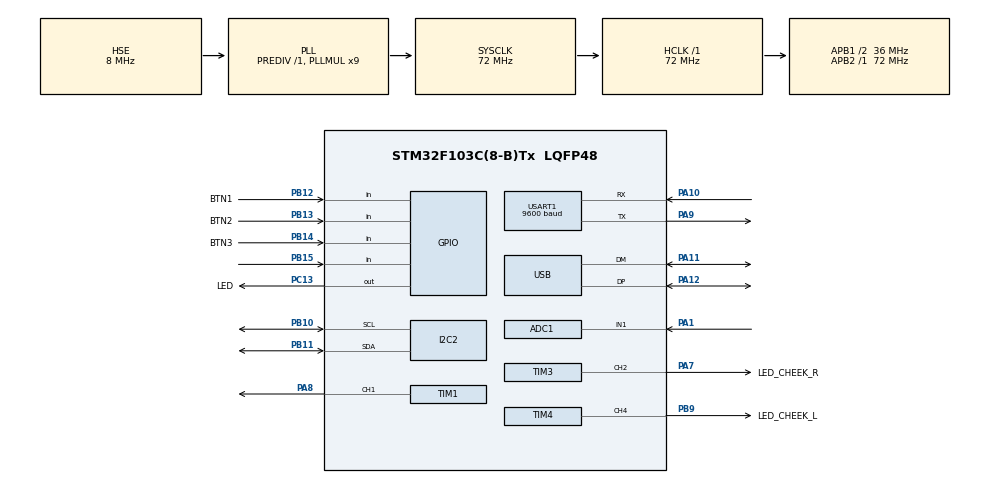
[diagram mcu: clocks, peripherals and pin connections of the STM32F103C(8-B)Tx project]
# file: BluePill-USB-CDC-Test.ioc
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ADC1.Channel-1\#ChannelRegularConversion=ADC_CHANNEL_1
ADC1.NbrOfConversionFlag=1
ADC1.Rank-1\#ChannelRegularConversion=1
ADC1.SamplingTime-1\#ChannelRegularConversion=ADC_SAMPLETIME_1CYCLE_5
ADC1.master=1
I2C2.I2C_Mode=I2C_Fast
Mcu.Family=STM32F1
Mcu.Name=STM32F103C(8-B)Tx
Mcu.Package=LQFP48
NVIC.PriorityGroup=NVIC_PRIORITYGROUP_4
NVIC.USB_LP_CAN1_RX0_IRQn=true\:0\:0\:false\:false\:true\:false\:true\:true
PA1.Signal=ADCx_IN1
PA10.Mode=Asynchronous
PA10.Signal=USART1_RX
PA11.Mode=Device
PA11.Signal=USB_DM
PA12.Mode=Device
PA12.Signal=USB_DP
PA13.Mode=Serial_Wire
PA13.Signal=SYS_JTMS-SWDIO
PA14.Mode=Serial_Wire
PA14.Signal=SYS_JTCK-SWCLK
PA7.GPIO_Label=LED_CHEEK_R
PA7.Signal=S_TIM3_CH2
PA8.Signal=S_TIM1_CH1
PA9.Mode=Asynchronous
PA9.Signal=USART1_TX
PB10.Mode=I2C
PB10.Signal=I2C2_SCL
PB11.Mode=I2C
PB11.Signal=I2C2_SDA
PB12.GPIO_Label=BTN1
PB12.Signal=GPIO_Input
PB13.GPIO_Label=BTN2
PB13.Signal=GPIO_Input
PB14.GPIO_Label=BTN3
PB14.Signal=GPIO_Input
PB15.Signal=GPIO_Input
PB9.GPIO_Label=LED_CHEEK_L
PB9.Signal=S_TIM4_CH4
PC13-TAMPER-RTC.GPIO_Label=LED
PC13-TAMPER-RTC.GPIO_PuPd=GPIO_PULLUP
PC13-TAMPER-RTC.PinState=GPIO_PIN_RESET
PC13-TAMPER-RTC.Signal=GPIO_Output
PD0-OSC_IN.Mode=HSE-External-Oscillator
PD0-OSC_IN.Signal=RCC_OSC_IN
PD1-OSC_OUT.Mode=HSE-External-Oscillator
PD1-OSC_OUT.Signal=RCC_OSC_OUT
ProjectManager.HeapSize=0x200
ProjectManager.StackSize=0x400
ProjectManager.TargetToolchain=STM32CubeIDE
RCC.AHBFreq_Value=72000000
RCC.APB1CLKDivider=RCC_HCLK_DIV2
RCC.APB1Freq_Value=36000000
RCC.APB1TimFreq_Value=72000000
RCC.APB2Freq_Value=72000000
RCC.APB2TimFreq_Value=72000000
RCC.HCLKFreq_Value=72000000
RCC.PLLMUL=RCC_PLL_MUL9
RCC.PLLSourceVirtual=RCC_PLLSOURCE_HSE
RCC.SYSCLKFreq_VALUE=72000000
RCC.SYSCLKSource=RCC_SYSCLKSOURCE_PLLCLK
RCC.USBFreq_Value=48000000
RCC.USBPrescaler=RCC_USBCLKSOURCE_PLL_DIV1_5
SH.ADCx_IN1.0=ADC1_IN1,IN1
SH.S_TIM1_CH1.0=TIM1_CH1,PWM Generation1 CH1
SH.S_TIM3_CH2.0=TIM3_CH2,PWM Generation2 CH2
SH.S_TIM4_CH4.0=TIM4_CH4,PWM Generation4 CH4
TIM1.Channel-PWM\ Generation1\ CH1=TIM_CHANNEL_1
TIM3.Channel-PWM\ Generation2\ CH2=TIM_CHANNEL_2
TIM4.Channel-PWM\ Generation4\ CH4=TIM_CHANNEL_4
USART1.BaudRate=9600
USART1.VirtualMode=VM_ASYNC
USB_DEVICE.CLASS_NAME_FS=CDC
USB_DEVICE.PRODUCT_STRING_CDC_FS=Test Product
USB_DEVICE.VirtualMode=Cdc
USB_DEVICE.VirtualModeFS=Cdc_FS
VP_RTC_VS_RTC_Activate.Mode=RTC_Enabled
VP_USB_DEVICE_VS_USB_DEVICE_CDC_FS.Mode=CDC_FS
board=custom

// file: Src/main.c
/* USER CODE BEGIN Header */
/**
  ******************************************************************************
  * @file           : main.c
  * @brief          : Main program body
  ******************************************************************************
  * @attention
  *
  * <h2><center>&copy; Copyright (c) 2021 STMicroelectronics.
  * All rights reserved.</center></h2>
  *
  * This software component is licensed by ST under BSD 3-Clause license,
  * the "License"; You may not use this file except in compliance with the
  * License. You may obtain a copy of the License at:
  *                        opensource.org/licenses/BSD-3-Clause
  *
  ******************************************************************************
  */
/* USER CODE END Header */
#include "main.h"
#include "adc.h"
#include "i2c.h"
#include "rtc.h"
#include "tim.h"
#include "usart.h"
#include "usb_device.h"
#include "gpio.h"

/* USER CODE BEGIN Includes */
#include "SEGGER_RTT.h"

#include "hw/led.h"
#include "hw/usb_cdc_comms.h"
#include "hw/oled.h"
#include "hw/flash.h"
/* USER CODE END Includes */

void SystemClock_Config(void);

int main(void)
{

  /* MCU Configuration--------------------------------------------------------*/

  /* Reset of all peripherals, Initializes the Flash interface and the Systick. */
  HAL_Init();

  /* Configure the system clock */
  SystemClock_Config();

  /* Initialize all configured peripherals */
  MX_GPIO_Init();
  MX_USB_DEVICE_Init();
  MX_I2C2_Init();
  MX_TIM3_Init();
  MX_TIM4_Init();
  MX_USART1_UART_Init();
  MX_TIM1_Init();
  MX_RTC_Init();
  MX_ADC1_Init();
  /* USER CODE BEGIN 2 */

  badge_init();
  //// User LED /////////////////////////////////////////////////////////////////
  // Flash LED briefly on reset
  HAL_GPIO_WritePin(LED_GPIO_Port, LED_Pin, GPIO_PIN_SET);
  HAL_Delay(500);
  HAL_GPIO_WritePin(LED_GPIO_Port, LED_Pin, GPIO_PIN_RESET);

  menu_badge();
  /* USER CODE END 2 */

  /* Infinite loop */
  /* USER CODE BEGIN WHILE */
  while(1){
    menu_badge();
    /* USER CODE END WHILE */

  }
}

void SystemClock_Config(void)
{
  RCC_OscInitTypeDef RCC_OscInitStruct = {0};
  RCC_ClkInitTypeDef RCC_ClkInitStruct = {0};
  RCC_PeriphCLKInitTypeDef PeriphClkInit = {0};

  /** Initializes the RCC Oscillators according to the specified parameters
  * in the RCC_OscInitTypeDef structure.
  */
  RCC_OscInitStruct.OscillatorType = RCC_OSCILLATORTYPE_LSI|RCC_OSCILLATORTYPE_HSE;
  RCC_OscInitStruct.HSEState = RCC_HSE_ON;
  RCC_OscInitStruct.HSEPredivValue = RCC_HSE_PREDIV_DIV1;
  RCC_OscInitStruct.HSIState = RCC_HSI_ON;
  RCC_OscInitStruct.LSIState = RCC_LSI_ON;
  RCC_OscInitStruct.PLL.PLLState = RCC_PLL_ON;
  RCC_OscInitStruct.PLL.PLLSource = RCC_PLLSOURCE_HSE;
  RCC_OscInitStruct.PLL.PLLMUL = RCC_PLL_MUL9;
  if (HAL_RCC_OscConfig(&RCC_OscInitStruct) != HAL_OK)
  {
    Error_Handler();
  }

  /** Initializes the CPU, AHB and APB buses clocks
  */
  RCC_ClkInitStruct.ClockType = RCC_CLOCKTYPE_HCLK|RCC_CLOCKTYPE_SYSCLK
                              |RCC_CLOCKTYPE_PCLK1|RCC_CLOCKTYPE_PCLK2;
  RCC_ClkInitStruct.SYSCLKSource = RCC_SYSCLKSOURCE_PLLCLK;
  RCC_ClkInitStruct.AHBCLKDivider = RCC_SYSCLK_DIV1;
  RCC_ClkInitStruct.APB1CLKDivider = RCC_HCLK_DIV2;
  RCC_ClkInitStruct.APB2CLKDivider = RCC_HCLK_DIV1;

  if (HAL_RCC_ClockConfig(&RCC_ClkInitStruct, FLASH_LATENCY_2) != HAL_OK)
  {
    Error_Handler();
  }
  PeriphClkInit.PeriphClockSelection = RCC_PERIPHCLK_RTC|RCC_PERIPHCLK_ADC
                              |RCC_PERIPHCLK_USB;
  PeriphClkInit.RTCClockSelection = RCC_RTCCLKSOURCE_LSI;
  PeriphClkInit.AdcClockSelection = RCC_ADCPCLK2_DIV2;
  PeriphClkInit.UsbClockSelection = RCC_USBCLKSOURCE_PLL_DIV1_5;
  if (HAL_RCCEx_PeriphCLKConfig(&PeriphClkInit) != HAL_OK)
  {
    Error_Handler();
  }
}

void Error_Handler(void)
{
  __disable_irq();
  while (1)
  {
  }
}
